# STM32WLE4C8U6 register map
File version: 1.0
Registers are 32-bit, access not given, reset 0x0 unless marked. A register's access mark holds for its fields unless they carry their own. Offsets are from the block's base; [hi:lo] are bit positions; {n}, {i} and the like mark numbered series.

## GPIO
Base 0x48001C00
0x1C00 MODER
  [7:6] MODE3
0x1C04 OTYPER
  [3] OT3
0x1C08 OSPEEDR
  [7:6] OSPEED3
0x1C0C PUPDR
  [7:6] PUPD3
0x1C10 IDR
  [3] ID3
0x1C14 ODR
  [3] OD3
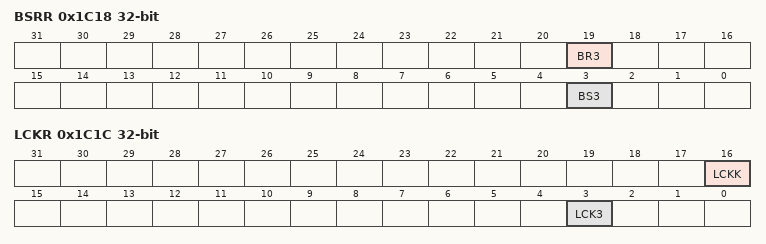
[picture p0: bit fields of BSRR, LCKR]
0x1C18 BSRR
  [19] BR3, [3] BS3
0x1C1C LCKR
  [16] LCKK, [3] LCK3
0x1C20 AFRL
  [15:12] AFSEL3
0x1C28 BRR
  [3] BR3

## RCC
Base 0x58000000
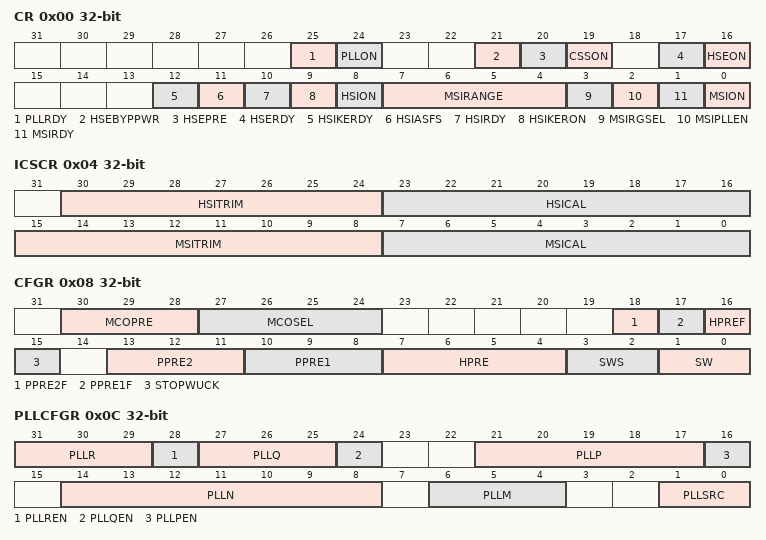
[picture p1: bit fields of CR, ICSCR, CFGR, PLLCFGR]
0x00 CR
  [25] PLLRDY, [24] PLLON, [21] HSEBYPPWR, [20] HSEPRE, [19] CSSON, [17] HSERDY, [16] HSEON, [12] HSIKERDY, [11] HSIASFS, [10] HSIRDY, [9] HSIKERON, [8] HSION, [7:4] MSIRANGE, [3] MSIRGSEL, [2] MSIPLLEN, [1] MSIRDY, [0] MSION
0x04 ICSCR
  [30:24] HSITRIM, [23:16] HSICAL, [15:8] MSITRIM, [7:0] MSICAL
0x08 CFGR
  [30:28] MCOPRE, [27:24] MCOSEL, [18] PPRE2F, [17] PPRE1F, [16] HPREF, [15] STOPWUCK, [13:11] PPRE2, [10:8] PPRE1, [7:4] HPRE, [3:2] SWS, [1:0] SW
0x0C PLLCFGR
  [31:29] PLLR, [28] PLLREN, [27:25] PLLQ, [24] PLLQEN, [21:17] PLLP, [16] PLLPEN, [14:8] PLLN, [6:4] PLLM, [1:0] PLLSRC
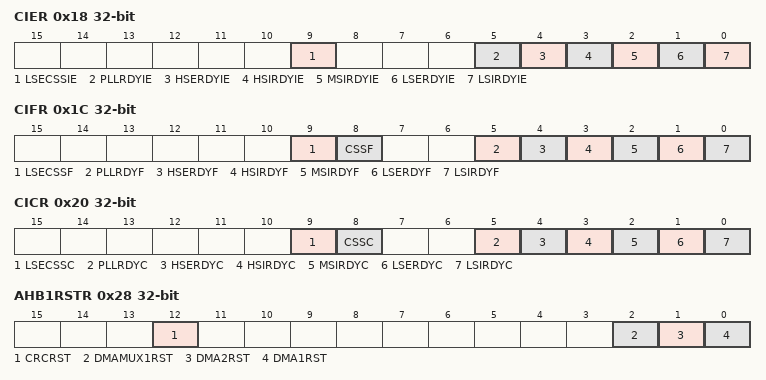
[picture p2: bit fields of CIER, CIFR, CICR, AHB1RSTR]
0x18 CIER
  [9] LSECSSIE, [5] PLLRDYIE, [4] HSERDYIE, [3] HSIRDYIE, [2] MSIRDYIE, [1] LSERDYIE, [0] LSIRDYIE
0x1C CIFR
  [9] LSECSSF, [8] CSSF, [5] PLLRDYF, [4] HSERDYF, [3] HSIRDYF, [2] MSIRDYF, [1] LSERDYF, [0] LSIRDYF
0x20 CICR
  [9] LSECSSC, [8] CSSC, [5] PLLRDYC, [4] HSERDYC, [3] HSIRDYC, [2] MSIRDYC, [1] LSERDYC, [0] LSIRDYC
0x28 AHB1RSTR
  [12] CRCRST, [2] DMAMUX1RST, [1] DMA2RST, [0] DMA1RST
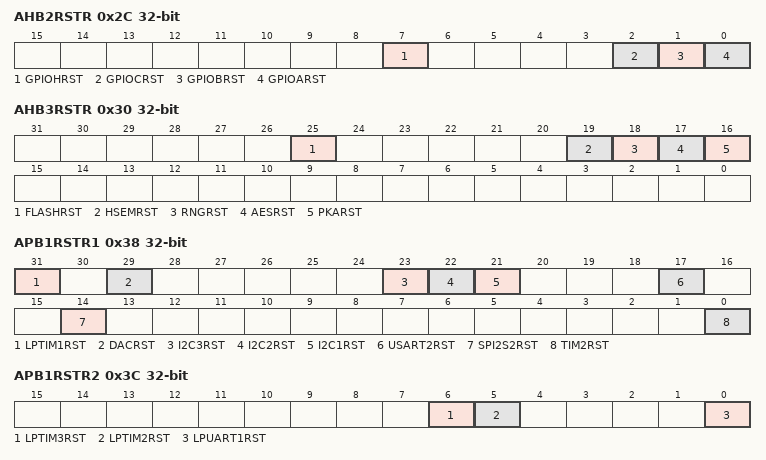
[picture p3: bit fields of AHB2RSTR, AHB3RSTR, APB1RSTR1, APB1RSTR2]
0x2C AHB2RSTR
  [7] GPIOHRST, [2] GPIOCRST, [1] GPIOBRST, [0] GPIOARST
0x30 AHB3RSTR
  [25] FLASHRST, [19] HSEMRST, [18] RNGRST, [17] AESRST, [16] PKARST
0x38 APB1RSTR1
  [31] LPTIM1RST, [29] DACRST, [23] I2C3RST, [22] I2C2RST, [21] I2C1RST, [17] USART2RST, [14] SPI2S2RST, [0] TIM2RST
0x3C APB1RSTR2
  [6] LPTIM3RST, [5] LPTIM2RST, [0] LPUART1RST
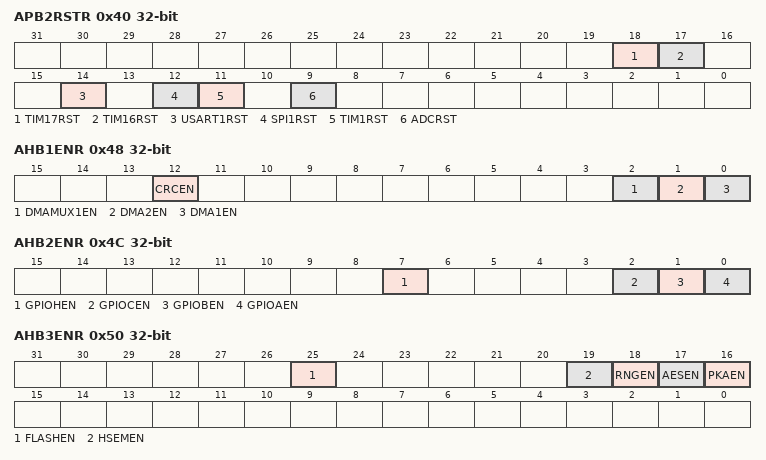
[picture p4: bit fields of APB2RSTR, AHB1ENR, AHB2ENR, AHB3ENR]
0x40 APB2RSTR
  [18] TIM17RST, [17] TIM16RST, [14] USART1RST, [12] SPI1RST, [11] TIM1RST, [9] ADCRST
0x44 APB3RSTR
  [0] SUBGHZSPIRST
0x48 AHB1ENR
  [12] CRCEN, [2] DMAMUX1EN, [1] DMA2EN, [0] DMA1EN
0x4C AHB2ENR
  [7] GPIOHEN, [2] GPIOCEN, [1] GPIOBEN, [0] GPIOAEN
0x50 AHB3ENR
  [25] FLASHEN, [19] HSEMEN, [18] RNGEN, [17] AESEN, [16] PKAEN
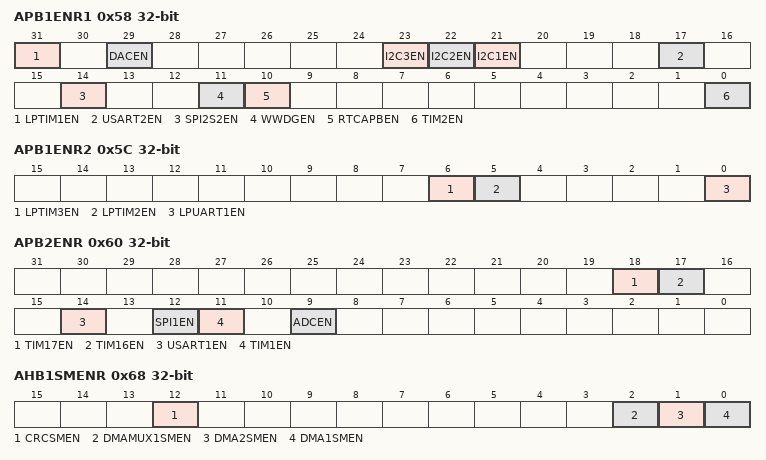
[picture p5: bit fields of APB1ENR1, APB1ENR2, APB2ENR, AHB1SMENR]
0x58 APB1ENR1
  [31] LPTIM1EN, [29] DACEN, [23] I2C3EN, [22] I2C2EN, [21] I2C1EN, [17] USART2EN, [14] SPI2S2EN, [11] WWDGEN, [10] RTCAPBEN, [0] TIM2EN
0x5C APB1ENR2
  [6] LPTIM3EN, [5] LPTIM2EN, [0] LPUART1EN
0x60 APB2ENR
  [18] TIM17EN, [17] TIM16EN, [14] USART1EN, [12] SPI1EN, [11] TIM1EN, [9] ADCEN
0x64 APB3ENR
  [0] SUBGHZSPIEN
0x68 AHB1SMENR
  [12] CRCSMEN, [2] DMAMUX1SMEN, [1] DMA2SMEN, [0] DMA1SMEN
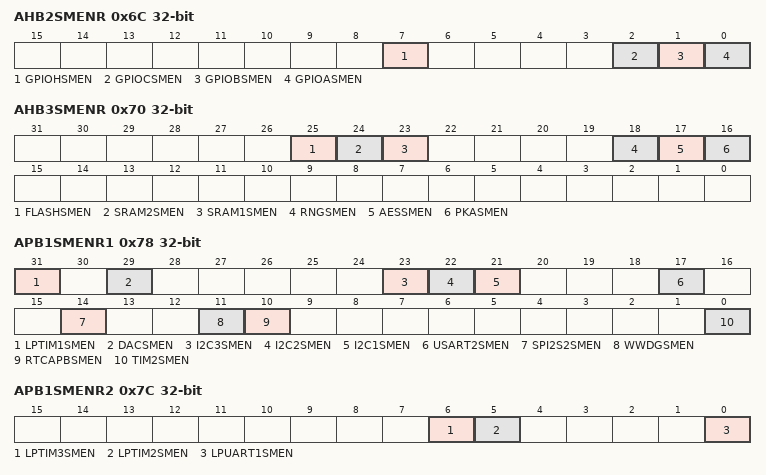
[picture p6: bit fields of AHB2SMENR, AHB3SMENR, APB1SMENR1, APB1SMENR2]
0x6C AHB2SMENR
  [7] GPIOHSMEN, [2] GPIOCSMEN, [1] GPIOBSMEN, [0] GPIOASMEN
0x70 AHB3SMENR
  [25] FLASHSMEN, [24] SRAM2SMEN, [23] SRAM1SMEN, [18] RNGSMEN, [17] AESSMEN, [16] PKASMEN
0x78 APB1SMENR1
  [31] LPTIM1SMEN, [29] DACSMEN, [23] I2C3SMEN, [22] I2C2SMEN, [21] I2C1SMEN, [17] USART2SMEN, [14] SPI2S2SMEN, [11] WWDGSMEN, [10] RTCAPBSMEN, [0] TIM2SMEN
0x7C APB1SMENR2
  [6] LPTIM3SMEN, [5] LPTIM2SMEN, [0] LPUART1SMEN
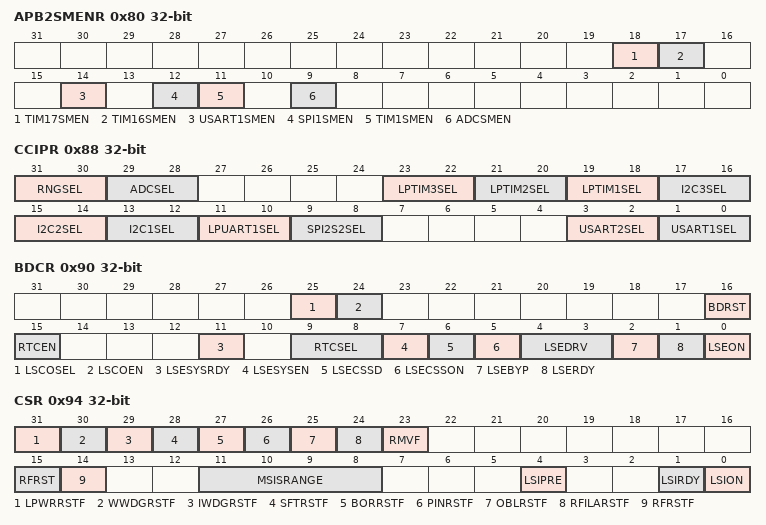
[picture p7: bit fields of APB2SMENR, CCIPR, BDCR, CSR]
0x80 APB2SMENR
  [18] TIM17SMEN, [17] TIM16SMEN, [14] USART1SMEN, [12] SPI1SMEN, [11] TIM1SMEN, [9] ADCSMEN
0x84 APB3SMENR
  [0] SUBGHZSPISMEN
0x88 CCIPR
  [31:30] RNGSEL, [29:28] ADCSEL, [23:22] LPTIM3SEL, [21:20] LPTIM2SEL, [19:18] LPTIM1SEL, [17:16] I2C3SEL, [15:14] I2C2SEL, [13:12] I2C1SEL, [11:10] LPUART1SEL, [9:8] SPI2S2SEL, [3:2] USART2SEL, [1:0] USART1SEL
0x90 BDCR
  [25] LSCOSEL, [24] LSCOEN, [16] BDRST, [15] RTCEN, [11] LSESYSRDY, [9:8] RTCSEL, [7] LSESYSEN, [6] LSECSSD, [5] LSECSSON, [4:3] LSEDRV, [2] LSEBYP, [1] LSERDY, [0] LSEON
0x94 CSR
  [31] LPWRRSTF, [30] WWDGRSTF, [29] IWDGRSTF, [28] SFTRSTF, [27] BORRSTF, [26] PINRSTF, [25] OBLRSTF, [24] RFILARSTF, [23] RMVF, [15] RFRST, [14] RFRSTF, [11:8] MSISRANGE, [4] LSIPRE, [1] LSIRDY, [0] LSION
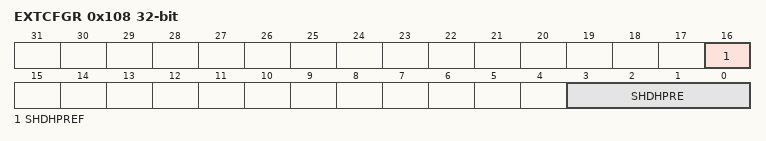
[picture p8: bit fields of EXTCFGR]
0x108 EXTCFGR
  [16] SHDHPREF, [3:0] SHDHPRE

## PWR
Base 0x58000400
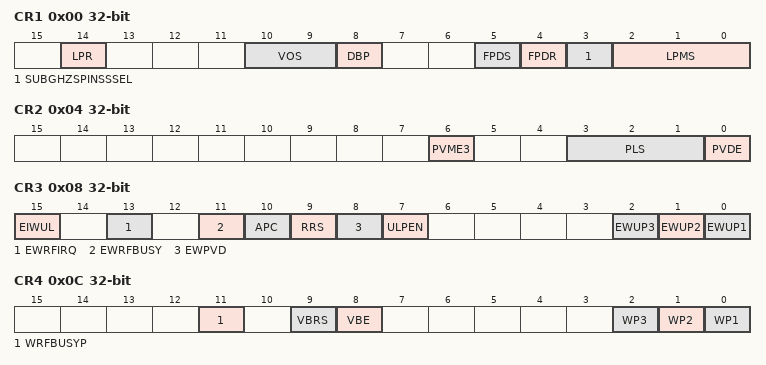
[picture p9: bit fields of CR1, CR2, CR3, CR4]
0x00 CR1
  [14] LPR, [10:9] VOS, [8] DBP, [5] FPDS, [4] FPDR, [3] SUBGHZSPINSSSEL, [2:0] LPMS
0x04 CR2
  [6] PVME3, [3:1] PLS, [0] PVDE
0x08 CR3
  [15] EIWUL, [13] EWRFIRQ, [11] EWRFBUSY, [10] APC, [9] RRS, [8] EWPVD, [7] ULPEN, [2] EWUP3, [1] EWUP2, [0] EWUP1
0x0C CR4
  [11] WRFBUSYP, [9] VBRS, [8] VBE, [2] WP3, [1] WP2, [0] WP1
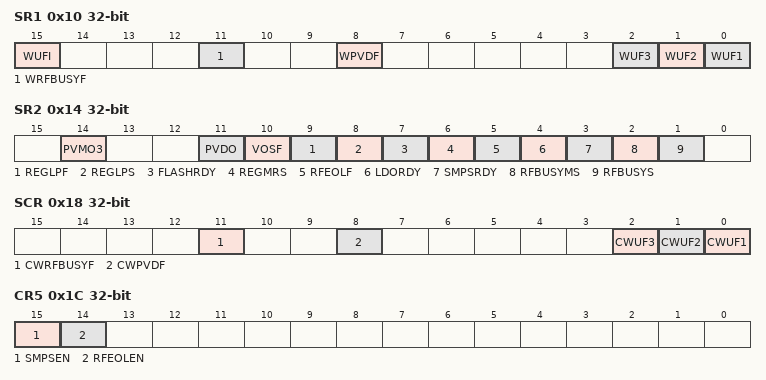
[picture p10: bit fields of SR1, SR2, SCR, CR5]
0x10 SR1
  [15] WUFI, [11] WRFBUSYF, [8] WPVDF, [2] WUF3, [1] WUF2, [0] WUF1
0x14 SR2
  [14] PVMO3, [11] PVDO, [10] VOSF, [9] REGLPF, [8] REGLPS, [7] FLASHRDY, [6] REGMRS, [5] RFEOLF, [4] LDORDY, [3] SMPSRDY, [2] RFBUSYMS, [1] RFBUSYS
0x18 SCR
  [11] CWRFBUSYF, [8] CWPVDF, [2] CWUF3, [1] CWUF2, [0] CWUF1
0x1C CR5
  [15] SMPSEN, [14] RFEOLEN
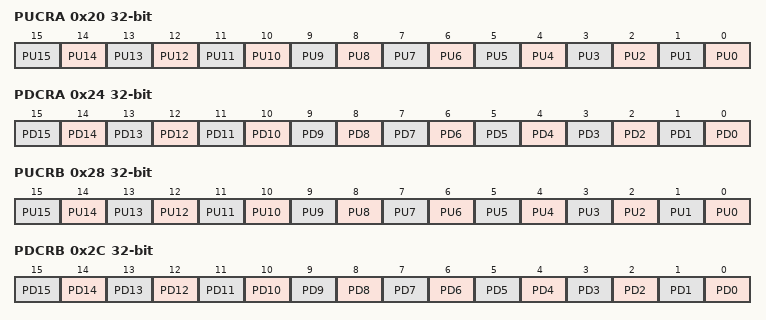
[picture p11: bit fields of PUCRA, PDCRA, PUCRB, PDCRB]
0x20 PUCRA
  [n] PU{n} (n=0..15)
0x24 PDCRA
  [n] PD{n} (n=0..15)
0x28 PUCRB
  [n] PU{n} (n=0..15)
0x2C PDCRB
  [n] PD{n} (n=0..15)
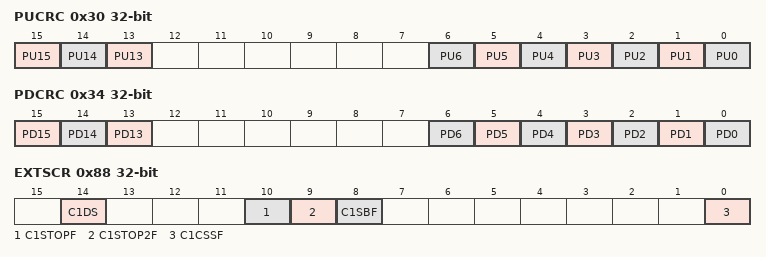
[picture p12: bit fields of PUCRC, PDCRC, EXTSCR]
0x30 PUCRC
  [15] PU15, [14] PU14, [13] PU13, [n] PU{n} (n=0..6)
0x34 PDCRC
  [15] PD15, [14] PD14, [13] PD13, [n] PD{n} (n=0..6)
0x58 PUCRH
  [3] PU3
0x5C PDCRH
  [3] PD3
0x88 EXTSCR
  [14] C1DS, [10] C1STOPF, [9] C1STOP2F, [8] C1SBF, [0] C1CSSF
0x90 SUBGHZSPICR
  [15] NSS
